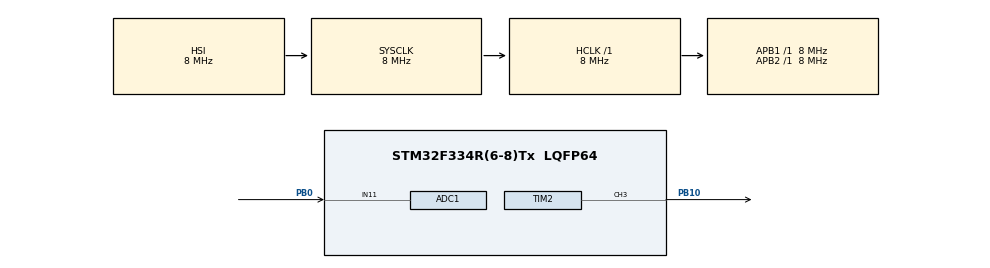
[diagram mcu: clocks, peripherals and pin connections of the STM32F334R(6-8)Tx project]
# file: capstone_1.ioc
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ADC1.Channel-0\#ChannelRegularConversion=ADC_CHANNEL_11
ADC1.NbrOfConversionFlag=1
ADC1.Offset-0\#ChannelRegularConversion=0
ADC1.OffsetNumber-0\#ChannelRegularConversion=ADC_OFFSET_NONE
ADC1.Rank-0\#ChannelRegularConversion=1
ADC1.SamplingTime-0\#ChannelRegularConversion=ADC_SAMPLETIME_1CYCLE_5
ADC1.SamplingTimeOPAMP-0\#ChannelRegularConversion=ADC_SAMPLETIME_61CYCLES_5
ADC1.SubFamily=STM32F334x8
ADC1.master=1
Mcu.Family=STM32F3
Mcu.Name=STM32F334R(6-8)Tx
Mcu.Package=LQFP64
NVIC.PriorityGroup=NVIC_PRIORITYGROUP_0
PB0.Mode=IN11-Single-Ended
PB0.Signal=ADC1_IN11
PB10.Signal=S_TIM2_CH3
ProjectManager.HeapSize=0x200
ProjectManager.StackSize=0x400
ProjectManager.TargetToolchain=STM32CubeIDE
RCC.AHBFreq_Value=8000000
RCC.APB1Freq_Value=8000000
RCC.APB1TimFreq_Value=8000000
RCC.APB2Freq_Value=8000000
RCC.APB2TimFreq_Value=8000000
RCC.CortexFreq_Value=8000000
RCC.FLatency-AdvancedSettings=FLASH_LATENCY_0
RCC.HCLKFreq_Value=8000000
RCC.HSE_VALUE=8000000
RCC.HSI_VALUE=8000000
RCC.LSE_VALUE=32768
RCC.PLLMUL=RCC_PLL_MUL16
RCC.SYSCLKFreq_VALUE=8000000
SH.S_TIM2_CH3.0=TIM2_CH3,PWM Generation3 CH3
TIM2.Channel-PWM\ Generation3\ CH3=TIM_CHANNEL_3
TIM2.Period=199
TIM2.Prescaler=8
VP_TIM2_VS_ClockSourceINT.Mode=Internal
board=NUCLEO-F334R8

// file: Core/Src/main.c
/* USER CODE BEGIN Header */
/**
  ******************************************************************************
  * @file           : main.c
  * @brief          : Main program body
  ******************************************************************************
  * @attention
  *
  * Copyright (c) 2023 STMicroelectronics.
  * All rights reserved.
  *
  * This software is licensed under terms that can be found in the LICENSE file
  * in the root directory of this software component.
  * If no LICENSE file comes with this software, it is provided AS-IS.
  *
  ******************************************************************************
  */
/* USER CODE END Header */
#include "main.h"

/* USER CODE BEGIN Includes */
#include "stm32f3xx_hal.h"

#include "stdint.h"

int32_t map(int32_t x, int32_t in_min, int32_t in_max, int32_t out_min, int32_t out_max) {
    return (x - in_min) * (out_max - out_min) / (in_max - in_min) + out_min;
}
/* USER CODE END Includes */

ADC_HandleTypeDef hadc1;

TIM_HandleTypeDef htim2;

void SystemClock_Config(void);
static void MX_GPIO_Init(void);
static void MX_ADC1_Init(void);
static void MX_TIM2_Init(void);

int main(void)
{

  /* MCU Configuration--------------------------------------------------------*/

  /* Reset of all peripherals, Initializes the Flash interface and the Systick. */
  HAL_Init();

  /* Configure the system clock */
  SystemClock_Config();

  /* Initialize all configured peripherals */
  MX_GPIO_Init();
  MX_ADC1_Init();
  MX_TIM2_Init();
  /* USER CODE BEGIN 2 */
  HAL_TIM_PWM_Start(&htim2, TIM_CHANNEL_3);
  /* USER CODE END 2 */

  /* Infinite loop */
  while (1)
  {

    /* USER CODE BEGIN 3 */

	  HAL_ADC_Start(&hadc1);
	      HAL_ADC_PollForConversion(&hadc1, HAL_MAX_DELAY);
	      uint16_t ldrValue = HAL_ADC_GetValue(&hadc1);

	      HAL_ADC_Stop(&hadc1);

	      // Map LDR value to PWM duty cycle
	      uint16_t dutyCycle = map(ldrValue,4095,0, 0, 100);

	      // Set PWM duty cycle for LED brightness
	      __HAL_TIM_SET_COMPARE(&htim2, TIM_CHANNEL_3, dutyCycle);

	      HAL_Delay(500); // Add a small delay
  }
  /* USER CODE END 3 */
}

void SystemClock_Config(void)
{
  RCC_OscInitTypeDef RCC_OscInitStruct = {0};
  RCC_ClkInitTypeDef RCC_ClkInitStruct = {0};
  RCC_PeriphCLKInitTypeDef PeriphClkInit = {0};

  /** Initializes the RCC Oscillators according to the specified parameters
  * in the RCC_OscInitTypeDef structure.
  */
  RCC_OscInitStruct.OscillatorType = RCC_OSCILLATORTYPE_HSI;
  RCC_OscInitStruct.HSIState = RCC_HSI_ON;
  RCC_OscInitStruct.HSICalibrationValue = RCC_HSICALIBRATION_DEFAULT;
  RCC_OscInitStruct.PLL.PLLState = RCC_PLL_ON;
  RCC_OscInitStruct.PLL.PLLSource = RCC_PLLSOURCE_HSI;
  RCC_OscInitStruct.PLL.PLLMUL = RCC_PLL_MUL16;
  if (HAL_RCC_OscConfig(&RCC_OscInitStruct) != HAL_OK)
  {
    Error_Handler();
  }

  /** Initializes the CPU, AHB and APB buses clocks
  */
  RCC_ClkInitStruct.ClockType = RCC_CLOCKTYPE_HCLK|RCC_CLOCKTYPE_SYSCLK
                              |RCC_CLOCKTYPE_PCLK1|RCC_CLOCKTYPE_PCLK2;
  RCC_ClkInitStruct.SYSCLKSource = RCC_SYSCLKSOURCE_HSI;
  RCC_ClkInitStruct.AHBCLKDivider = RCC_SYSCLK_DIV1;
  RCC_ClkInitStruct.APB1CLKDivider = RCC_HCLK_DIV1;
  RCC_ClkInitStruct.APB2CLKDivider = RCC_HCLK_DIV1;

  if (HAL_RCC_ClockConfig(&RCC_ClkInitStruct, FLASH_LATENCY_0) != HAL_OK)
  {
    Error_Handler();
  }
  PeriphClkInit.PeriphClockSelection = RCC_PERIPHCLK_ADC12;
  PeriphClkInit.Adc12ClockSelection = RCC_ADC12PLLCLK_DIV1;
  if (HAL_RCCEx_PeriphCLKConfig(&PeriphClkInit) != HAL_OK)
  {
    Error_Handler();
  }
}

static void MX_ADC1_Init(void)
{

  ADC_MultiModeTypeDef multimode = {0};
  ADC_ChannelConfTypeDef sConfig = {0};

  /** Common config
  */
  hadc1.Instance = ADC1;
  hadc1.Init.ClockPrescaler = ADC_CLOCK_ASYNC_DIV1;
  hadc1.Init.Resolution = ADC_RESOLUTION_12B;
  hadc1.Init.ScanConvMode = ADC_SCAN_DISABLE;
  hadc1.Init.ContinuousConvMode = DISABLE;
  hadc1.Init.DiscontinuousConvMode = DISABLE;
  hadc1.Init.ExternalTrigConvEdge = ADC_EXTERNALTRIGCONVEDGE_NONE;
  hadc1.Init.ExternalTrigConv = ADC_SOFTWARE_START;
  hadc1.Init.DataAlign = ADC_DATAALIGN_RIGHT;
  hadc1.Init.NbrOfConversion = 1;
  hadc1.Init.DMAContinuousRequests = DISABLE;
  hadc1.Init.EOCSelection = ADC_EOC_SINGLE_CONV;
  hadc1.Init.LowPowerAutoWait = DISABLE;
  hadc1.Init.Overrun = ADC_OVR_DATA_OVERWRITTEN;
  if (HAL_ADC_Init(&hadc1) != HAL_OK)
  {
    Error_Handler();
  }

  /** Configure the ADC multi-mode
  */
  multimode.Mode = ADC_MODE_INDEPENDENT;
  if (HAL_ADCEx_MultiModeConfigChannel(&hadc1, &multimode) != HAL_OK)
  {
    Error_Handler();
  }

  /** Configure Regular Channel
  */
  sConfig.Channel = ADC_CHANNEL_11;
  sConfig.Rank = ADC_REGULAR_RANK_1;
  sConfig.SingleDiff = ADC_SINGLE_ENDED;
  sConfig.SamplingTime = ADC_SAMPLETIME_1CYCLE_5;
  sConfig.OffsetNumber = ADC_OFFSET_NONE;
  sConfig.Offset = 0;
  if (HAL_ADC_ConfigChannel(&hadc1, &sConfig) != HAL_OK)
  {
    Error_Handler();
  }

}

static void MX_TIM2_Init(void)
{

  TIM_ClockConfigTypeDef sClockSourceConfig = {0};
  TIM_MasterConfigTypeDef sMasterConfig = {0};
  TIM_OC_InitTypeDef sConfigOC = {0};

  htim2.Instance = TIM2;
  htim2.Init.Prescaler = 8;
  htim2.Init.CounterMode = TIM_COUNTERMODE_UP;
  htim2.Init.Period = 199;
  htim2.Init.ClockDivision = TIM_CLOCKDIVISION_DIV1;
  htim2.Init.AutoReloadPreload = TIM_AUTORELOAD_PRELOAD_DISABLE;
  if (HAL_TIM_Base_Init(&htim2) != HAL_OK)
  {
    Error_Handler();
  }
  sClockSourceConfig.ClockSource = TIM_CLOCKSOURCE_INTERNAL;
  if (HAL_TIM_ConfigClockSource(&htim2, &sClockSourceConfig) != HAL_OK)
  {
    Error_Handler();
  }
  if (HAL_TIM_PWM_Init(&htim2) != HAL_OK)
  {
    Error_Handler();
  }
  sMasterConfig.MasterOutputTrigger = TIM_TRGO_RESET;
  sMasterConfig.MasterSlaveMode = TIM_MASTERSLAVEMODE_DISABLE;
  if (HAL_TIMEx_MasterConfigSynchronization(&htim2, &sMasterConfig) != HAL_OK)
  {
    Error_Handler();
  }
  sConfigOC.OCMode = TIM_OCMODE_PWM1;
  sConfigOC.Pulse = 0;
  sConfigOC.OCPolarity = TIM_OCPOLARITY_HIGH;
  sConfigOC.OCFastMode = TIM_OCFAST_DISABLE;
  if (HAL_TIM_PWM_ConfigChannel(&htim2, &sConfigOC, TIM_CHANNEL_3) != HAL_OK)
  {
    Error_Handler();
  }
  HAL_TIM_MspPostInit(&htim2);

}

static void MX_GPIO_Init(void)
{

  /* GPIO Ports Clock Enable */
  __HAL_RCC_GPIOB_CLK_ENABLE();

}

void Error_Handler(void)
{
  __disable_irq();
  while (1)
  {
  }
}
